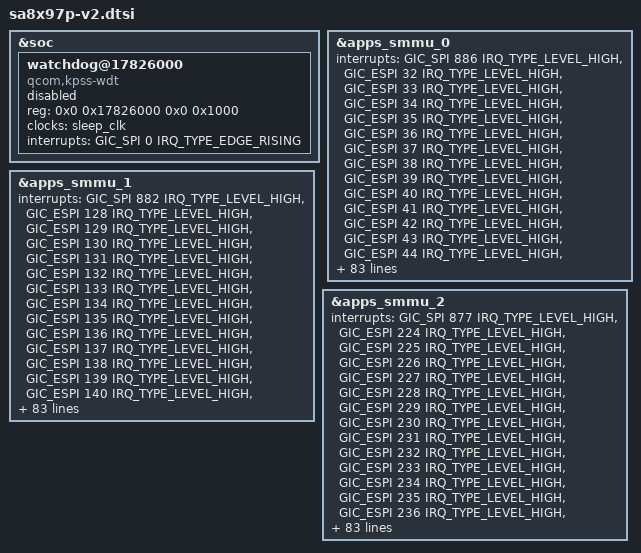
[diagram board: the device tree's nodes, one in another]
// SPDX-License-Identifier: BSD-3-Clause
/*
 * Copyright (c) Qualcomm Technologies, Inc. and/or its subsidiaries.
 */

&soc {
	/delete-node/ watchdog@17821000;

	watchdog@17826000 {
		compatible = "qcom,kpss-wdt";
		reg = <0x0 0x17826000 0x0 0x1000>;
		clocks = <&sleep_clk>;
		interrupts = <GIC_SPI 0 IRQ_TYPE_EDGE_RISING>;
		status = "disabled";
	};
};

&apps_smmu_0 {
	interrupts =	<GIC_SPI 886 IRQ_TYPE_LEVEL_HIGH>,
			<GIC_ESPI 32 IRQ_TYPE_LEVEL_HIGH>,
			<GIC_ESPI 33 IRQ_TYPE_LEVEL_HIGH>,
			<GIC_ESPI 34 IRQ_TYPE_LEVEL_HIGH>,
			<GIC_ESPI 35 IRQ_TYPE_LEVEL_HIGH>,
			<GIC_ESPI 36 IRQ_TYPE_LEVEL_HIGH>,
			<GIC_ESPI 37 IRQ_TYPE_LEVEL_HIGH>,
			<GIC_ESPI 38 IRQ_TYPE_LEVEL_HIGH>,
			<GIC_ESPI 39 IRQ_TYPE_LEVEL_HIGH>,
			<GIC_ESPI 40 IRQ_TYPE_LEVEL_HIGH>,
			<GIC_ESPI 41 IRQ_TYPE_LEVEL_HIGH>,
			<GIC_ESPI 42 IRQ_TYPE_LEVEL_HIGH>,
			<GIC_ESPI 43 IRQ_TYPE_LEVEL_HIGH>,
			<GIC_ESPI 44 IRQ_TYPE_LEVEL_HIGH>,
			<GIC_ESPI 45 IRQ_TYPE_LEVEL_HIGH>,
			<GIC_ESPI 46 IRQ_TYPE_LEVEL_HIGH>,
			<GIC_ESPI 47 IRQ_TYPE_LEVEL_HIGH>,
			<GIC_ESPI 48 IRQ_TYPE_LEVEL_HIGH>,
			<GIC_ESPI 49 IRQ_TYPE_LEVEL_HIGH>,
			<GIC_ESPI 50 IRQ_TYPE_LEVEL_HIGH>,
			<GIC_ESPI 51 IRQ_TYPE_LEVEL_HIGH>,
			<GIC_ESPI 52 IRQ_TYPE_LEVEL_HIGH>,
			<GIC_ESPI 53 IRQ_TYPE_LEVEL_HIGH>,
			<GIC_ESPI 54 IRQ_TYPE_LEVEL_HIGH>,
			<GIC_ESPI 55 IRQ_TYPE_LEVEL_HIGH>,
			<GIC_ESPI 56 IRQ_TYPE_LEVEL_HIGH>,
			<GIC_ESPI 57 IRQ_TYPE_LEVEL_HIGH>,
			<GIC_ESPI 58 IRQ_TYPE_LEVEL_HIGH>,
			<GIC_ESPI 59 IRQ_TYPE_LEVEL_HIGH>,
			<GIC_ESPI 60 IRQ_TYPE_LEVEL_HIGH>,
			<GIC_ESPI 61 IRQ_TYPE_LEVEL_HIGH>,
			<GIC_ESPI 62 IRQ_TYPE_LEVEL_HIGH>,
			<GIC_ESPI 63 IRQ_TYPE_LEVEL_HIGH>,
			<GIC_ESPI 64 IRQ_TYPE_LEVEL_HIGH>,
			<GIC_ESPI 65 IRQ_TYPE_LEVEL_HIGH>,
			<GIC_ESPI 66 IRQ_TYPE_LEVEL_HIGH>,
			<GIC_ESPI 67 IRQ_TYPE_LEVEL_HIGH>,
			<GIC_ESPI 68 IRQ_TYPE_LEVEL_HIGH>,
			<GIC_ESPI 69 IRQ_TYPE_LEVEL_HIGH>,
			<GIC_ESPI 70 IRQ_TYPE_LEVEL_HIGH>,
			<GIC_ESPI 71 IRQ_TYPE_LEVEL_HIGH>,
			<GIC_ESPI 72 IRQ_TYPE_LEVEL_HIGH>,
			<GIC_ESPI 73 IRQ_TYPE_LEVEL_HIGH>,
			<GIC_ESPI 74 IRQ_TYPE_LEVEL_HIGH>,
			<GIC_ESPI 75 IRQ_TYPE_LEVEL_HIGH>,
			<GIC_ESPI 76 IRQ_TYPE_LEVEL_HIGH>,
			<GIC_ESPI 77 IRQ_TYPE_LEVEL_HIGH>,
			<GIC_ESPI 78 IRQ_TYPE_LEVEL_HIGH>,
			<GIC_ESPI 79 IRQ_TYPE_LEVEL_HIGH>,
			<GIC_ESPI 80 IRQ_TYPE_LEVEL_HIGH>,
			<GIC_ESPI 81 IRQ_TYPE_LEVEL_HIGH>,
			<GIC_ESPI 82 IRQ_TYPE_LEVEL_HIGH>,
			<GIC_ESPI 83 IRQ_TYPE_LEVEL_HIGH>,
			<GIC_ESPI 84 IRQ_TYPE_LEVEL_HIGH>,
			<GIC_ESPI 85 IRQ_TYPE_LEVEL_HIGH>,
			<GIC_ESPI 86 IRQ_TYPE_LEVEL_HIGH>,
			<GIC_ESPI 87 IRQ_TYPE_LEVEL_HIGH>,
			<GIC_ESPI 88 IRQ_TYPE_LEVEL_HIGH>,
			<GIC_ESPI 89 IRQ_TYPE_LEVEL_HIGH>,
			<GIC_ESPI 90 IRQ_TYPE_LEVEL_HIGH>,
			<GIC_ESPI 91 IRQ_TYPE_LEVEL_HIGH>,
			<GIC_ESPI 92 IRQ_TYPE_LEVEL_HIGH>,
			<GIC_ESPI 93 IRQ_TYPE_LEVEL_HIGH>,
			<GIC_ESPI 94 IRQ_TYPE_LEVEL_HIGH>,
			<GIC_ESPI 95 IRQ_TYPE_LEVEL_HIGH>,
			<GIC_ESPI 96 IRQ_TYPE_LEVEL_HIGH>,
			<GIC_ESPI 97 IRQ_TYPE_LEVEL_HIGH>,
			<GIC_ESPI 98 IRQ_TYPE_LEVEL_HIGH>,
			<GIC_ESPI 99 IRQ_TYPE_LEVEL_HIGH>,
			<GIC_ESPI 100 IRQ_TYPE_LEVEL_HIGH>,
			<GIC_ESPI 101 IRQ_TYPE_LEVEL_HIGH>,
			<GIC_ESPI 102 IRQ_TYPE_LEVEL_HIGH>,
			<GIC_ESPI 103 IRQ_TYPE_LEVEL_HIGH>,
			<GIC_ESPI 104 IRQ_TYPE_LEVEL_HIGH>,
			<GIC_ESPI 105 IRQ_TYPE_LEVEL_HIGH>,
			<GIC_ESPI 106 IRQ_TYPE_LEVEL_HIGH>,
			<GIC_ESPI 107 IRQ_TYPE_LEVEL_HIGH>,
			<GIC_ESPI 108 IRQ_TYPE_LEVEL_HIGH>,
			<GIC_ESPI 109 IRQ_TYPE_LEVEL_HIGH>,
			<GIC_ESPI 110 IRQ_TYPE_LEVEL_HIGH>,
			<GIC_ESPI 111 IRQ_TYPE_LEVEL_HIGH>,
			<GIC_ESPI 112 IRQ_TYPE_LEVEL_HIGH>,
			<GIC_ESPI 113 IRQ_TYPE_LEVEL_HIGH>,
			<GIC_ESPI 114 IRQ_TYPE_LEVEL_HIGH>,
			<GIC_ESPI 115 IRQ_TYPE_LEVEL_HIGH>,
			<GIC_ESPI 116 IRQ_TYPE_LEVEL_HIGH>,
			<GIC_ESPI 117 IRQ_TYPE_LEVEL_HIGH>,
			<GIC_ESPI 118 IRQ_TYPE_LEVEL_HIGH>,
			<GIC_ESPI 119 IRQ_TYPE_LEVEL_HIGH>,
			<GIC_ESPI 120 IRQ_TYPE_LEVEL_HIGH>,
			<GIC_ESPI 121 IRQ_TYPE_LEVEL_HIGH>,
			<GIC_ESPI 122 IRQ_TYPE_LEVEL_HIGH>,
			<GIC_ESPI 123 IRQ_TYPE_LEVEL_HIGH>,
			<GIC_ESPI 124 IRQ_TYPE_LEVEL_HIGH>,
			<GIC_ESPI 125 IRQ_TYPE_LEVEL_HIGH>,
			<GIC_ESPI 126 IRQ_TYPE_LEVEL_HIGH>,
			<GIC_ESPI 127 IRQ_TYPE_LEVEL_HIGH>;
};

&apps_smmu_1 {
	interrupts =	<GIC_SPI 882 IRQ_TYPE_LEVEL_HIGH>,
			<GIC_ESPI 128 IRQ_TYPE_LEVEL_HIGH>,
			<GIC_ESPI 129 IRQ_TYPE_LEVEL_HIGH>,
			<GIC_ESPI 130 IRQ_TYPE_LEVEL_HIGH>,
			<GIC_ESPI 131 IRQ_TYPE_LEVEL_HIGH>,
			<GIC_ESPI 132 IRQ_TYPE_LEVEL_HIGH>,
			<GIC_ESPI 133 IRQ_TYPE_LEVEL_HIGH>,
			<GIC_ESPI 134 IRQ_TYPE_LEVEL_HIGH>,
			<GIC_ESPI 135 IRQ_TYPE_LEVEL_HIGH>,
			<GIC_ESPI 136 IRQ_TYPE_LEVEL_HIGH>,
			<GIC_ESPI 137 IRQ_TYPE_LEVEL_HIGH>,
			<GIC_ESPI 138 IRQ_TYPE_LEVEL_HIGH>,
			<GIC_ESPI 139 IRQ_TYPE_LEVEL_HIGH>,
			<GIC_ESPI 140 IRQ_TYPE_LEVEL_HIGH>,
			<GIC_ESPI 141 IRQ_TYPE_LEVEL_HIGH>,
			<GIC_ESPI 142 IRQ_TYPE_LEVEL_HIGH>,
			<GIC_ESPI 143 IRQ_TYPE_LEVEL_HIGH>,
			<GIC_ESPI 144 IRQ_TYPE_LEVEL_HIGH>,
			<GIC_ESPI 145 IRQ_TYPE_LEVEL_HIGH>,
			<GIC_ESPI 146 IRQ_TYPE_LEVEL_HIGH>,
			<GIC_ESPI 147 IRQ_TYPE_LEVEL_HIGH>,
			<GIC_ESPI 148 IRQ_TYPE_LEVEL_HIGH>,
			<GIC_ESPI 149 IRQ_TYPE_LEVEL_HIGH>,
			<GIC_ESPI 150 IRQ_TYPE_LEVEL_HIGH>,
			<GIC_ESPI 151 IRQ_TYPE_LEVEL_HIGH>,
			<GIC_ESPI 152 IRQ_TYPE_LEVEL_HIGH>,
			<GIC_ESPI 153 IRQ_TYPE_LEVEL_HIGH>,
			<GIC_ESPI 154 IRQ_TYPE_LEVEL_HIGH>,
			<GIC_ESPI 155 IRQ_TYPE_LEVEL_HIGH>,
			<GIC_ESPI 156 IRQ_TYPE_LEVEL_HIGH>,
			<GIC_ESPI 157 IRQ_TYPE_LEVEL_HIGH>,
			<GIC_ESPI 158 IRQ_TYPE_LEVEL_HIGH>,
			<GIC_ESPI 159 IRQ_TYPE_LEVEL_HIGH>,
			<GIC_ESPI 160 IRQ_TYPE_LEVEL_HIGH>,
			<GIC_ESPI 161 IRQ_TYPE_LEVEL_HIGH>,
			<GIC_ESPI 162 IRQ_TYPE_LEVEL_HIGH>,
			<GIC_ESPI 163 IRQ_TYPE_LEVEL_HIGH>,
			<GIC_ESPI 164 IRQ_TYPE_LEVEL_HIGH>,
			<GIC_ESPI 165 IRQ_TYPE_LEVEL_HIGH>,
			<GIC_ESPI 166 IRQ_TYPE_LEVEL_HIGH>,
			<GIC_ESPI 167 IRQ_TYPE_LEVEL_HIGH>,
			<GIC_ESPI 168 IRQ_TYPE_LEVEL_HIGH>,
			<GIC_ESPI 169 IRQ_TYPE_LEVEL_HIGH>,
			<GIC_ESPI 170 IRQ_TYPE_LEVEL_HIGH>,
			<GIC_ESPI 171 IRQ_TYPE_LEVEL_HIGH>,
			<GIC_ESPI 172 IRQ_TYPE_LEVEL_HIGH>,
			<GIC_ESPI 173 IRQ_TYPE_LEVEL_HIGH>,
			<GIC_ESPI 174 IRQ_TYPE_LEVEL_HIGH>,
			<GIC_ESPI 175 IRQ_TYPE_LEVEL_HIGH>,
			<GIC_ESPI 176 IRQ_TYPE_LEVEL_HIGH>,
			<GIC_ESPI 177 IRQ_TYPE_LEVEL_HIGH>,
			<GIC_ESPI 178 IRQ_TYPE_LEVEL_HIGH>,
			<GIC_ESPI 179 IRQ_TYPE_LEVEL_HIGH>,
			<GIC_ESPI 180 IRQ_TYPE_LEVEL_HIGH>,
			<GIC_ESPI 181 IRQ_TYPE_LEVEL_HIGH>,
			<GIC_ESPI 182 IRQ_TYPE_LEVEL_HIGH>,
			<GIC_ESPI 183 IRQ_TYPE_LEVEL_HIGH>,
			<GIC_ESPI 184 IRQ_TYPE_LEVEL_HIGH>,
			<GIC_ESPI 185 IRQ_TYPE_LEVEL_HIGH>,
			<GIC_ESPI 186 IRQ_TYPE_LEVEL_HIGH>,
			<GIC_ESPI 187 IRQ_TYPE_LEVEL_HIGH>,
			<GIC_ESPI 188 IRQ_TYPE_LEVEL_HIGH>,
			<GIC_ESPI 189 IRQ_TYPE_LEVEL_HIGH>,
			<GIC_ESPI 190 IRQ_TYPE_LEVEL_HIGH>,
			<GIC_ESPI 191 IRQ_TYPE_LEVEL_HIGH>,
			<GIC_ESPI 192 IRQ_TYPE_LEVEL_HIGH>,
			<GIC_ESPI 193 IRQ_TYPE_LEVEL_HIGH>,
			<GIC_ESPI 194 IRQ_TYPE_LEVEL_HIGH>,
			<GIC_ESPI 195 IRQ_TYPE_LEVEL_HIGH>,
			<GIC_ESPI 196 IRQ_TYPE_LEVEL_HIGH>,
			<GIC_ESPI 197 IRQ_TYPE_LEVEL_HIGH>,
			<GIC_ESPI 198 IRQ_TYPE_LEVEL_HIGH>,
			<GIC_ESPI 199 IRQ_TYPE_LEVEL_HIGH>,
			<GIC_ESPI 200 IRQ_TYPE_LEVEL_HIGH>,
			<GIC_ESPI 201 IRQ_TYPE_LEVEL_HIGH>,
			<GIC_ESPI 202 IRQ_TYPE_LEVEL_HIGH>,
			<GIC_ESPI 203 IRQ_TYPE_LEVEL_HIGH>,
			<GIC_ESPI 204 IRQ_TYPE_LEVEL_HIGH>,
			<GIC_ESPI 205 IRQ_TYPE_LEVEL_HIGH>,
			<GIC_ESPI 206 IRQ_TYPE_LEVEL_HIGH>,
			<GIC_ESPI 207 IRQ_TYPE_LEVEL_HIGH>,
			<GIC_ESPI 208 IRQ_TYPE_LEVEL_HIGH>,
			<GIC_ESPI 209 IRQ_TYPE_LEVEL_HIGH>,
			<GIC_ESPI 210 IRQ_TYPE_LEVEL_HIGH>,
			<GIC_ESPI 211 IRQ_TYPE_LEVEL_HIGH>,
			<GIC_ESPI 212 IRQ_TYPE_LEVEL_HIGH>,
			<GIC_ESPI 213 IRQ_TYPE_LEVEL_HIGH>,
			<GIC_ESPI 214 IRQ_TYPE_LEVEL_HIGH>,
			<GIC_ESPI 215 IRQ_TYPE_LEVEL_HIGH>,
			<GIC_ESPI 216 IRQ_TYPE_LEVEL_HIGH>,
			<GIC_ESPI 217 IRQ_TYPE_LEVEL_HIGH>,
			<GIC_ESPI 218 IRQ_TYPE_LEVEL_HIGH>,
			<GIC_ESPI 219 IRQ_TYPE_LEVEL_HIGH>,
			<GIC_ESPI 220 IRQ_TYPE_LEVEL_HIGH>,
			<GIC_ESPI 221 IRQ_TYPE_LEVEL_HIGH>,
			<GIC_ESPI 222 IRQ_TYPE_LEVEL_HIGH>,
			<GIC_ESPI 223 IRQ_TYPE_LEVEL_HIGH>;
};

&apps_smmu_2 {
	interrupts =	<GIC_SPI 877 IRQ_TYPE_LEVEL_HIGH>,
			<GIC_ESPI 224 IRQ_TYPE_LEVEL_HIGH>,
			<GIC_ESPI 225 IRQ_TYPE_LEVEL_HIGH>,
			<GIC_ESPI 226 IRQ_TYPE_LEVEL_HIGH>,
			<GIC_ESPI 227 IRQ_TYPE_LEVEL_HIGH>,
			<GIC_ESPI 228 IRQ_TYPE_LEVEL_HIGH>,
			<GIC_ESPI 229 IRQ_TYPE_LEVEL_HIGH>,
			<GIC_ESPI 230 IRQ_TYPE_LEVEL_HIGH>,
			<GIC_ESPI 231 IRQ_TYPE_LEVEL_HIGH>,
			<GIC_ESPI 232 IRQ_TYPE_LEVEL_HIGH>,
			<GIC_ESPI 233 IRQ_TYPE_LEVEL_HIGH>,
			<GIC_ESPI 234 IRQ_TYPE_LEVEL_HIGH>,
			<GIC_ESPI 235 IRQ_TYPE_LEVEL_HIGH>,
			<GIC_ESPI 236 IRQ_TYPE_LEVEL_HIGH>,
			<GIC_ESPI 237 IRQ_TYPE_LEVEL_HIGH>,
			<GIC_ESPI 238 IRQ_TYPE_LEVEL_HIGH>,
			<GIC_ESPI 239 IRQ_TYPE_LEVEL_HIGH>,
			<GIC_ESPI 240 IRQ_TYPE_LEVEL_HIGH>,
			<GIC_ESPI 241 IRQ_TYPE_LEVEL_HIGH>,
			<GIC_ESPI 242 IRQ_TYPE_LEVEL_HIGH>,
			<GIC_ESPI 243 IRQ_TYPE_LEVEL_HIGH>,
			<GIC_ESPI 244 IRQ_TYPE_LEVEL_HIGH>,
			<GIC_ESPI 245 IRQ_TYPE_LEVEL_HIGH>,
			<GIC_ESPI 246 IRQ_TYPE_LEVEL_HIGH>,
			<GIC_ESPI 247 IRQ_TYPE_LEVEL_HIGH>,
			<GIC_ESPI 248 IRQ_TYPE_LEVEL_HIGH>,
			<GIC_ESPI 249 IRQ_TYPE_LEVEL_HIGH>,
			<GIC_ESPI 250 IRQ_TYPE_LEVEL_HIGH>,
			<GIC_ESPI 251 IRQ_TYPE_LEVEL_HIGH>,
			<GIC_ESPI 252 IRQ_TYPE_LEVEL_HIGH>,
			<GIC_ESPI 253 IRQ_TYPE_LEVEL_HIGH>,
			<GIC_ESPI 254 IRQ_TYPE_LEVEL_HIGH>,
			<GIC_ESPI 255 IRQ_TYPE_LEVEL_HIGH>,
			<GIC_ESPI 256 IRQ_TYPE_LEVEL_HIGH>,
			<GIC_ESPI 257 IRQ_TYPE_LEVEL_HIGH>,
			<GIC_ESPI 258 IRQ_TYPE_LEVEL_HIGH>,
			<GIC_ESPI 259 IRQ_TYPE_LEVEL_HIGH>,
			<GIC_ESPI 260 IRQ_TYPE_LEVEL_HIGH>,
			<GIC_ESPI 261 IRQ_TYPE_LEVEL_HIGH>,
			<GIC_ESPI 262 IRQ_TYPE_LEVEL_HIGH>,
			<GIC_ESPI 263 IRQ_TYPE_LEVEL_HIGH>,
			<GIC_ESPI 264 IRQ_TYPE_LEVEL_HIGH>,
			<GIC_ESPI 265 IRQ_TYPE_LEVEL_HIGH>,
			<GIC_ESPI 266 IRQ_TYPE_LEVEL_HIGH>,
			<GIC_ESPI 267 IRQ_TYPE_LEVEL_HIGH>,
			<GIC_ESPI 268 IRQ_TYPE_LEVEL_HIGH>,
			<GIC_ESPI 269 IRQ_TYPE_LEVEL_HIGH>,
			<GIC_ESPI 270 IRQ_TYPE_LEVEL_HIGH>,
			<GIC_ESPI 271 IRQ_TYPE_LEVEL_HIGH>,
			<GIC_ESPI 272 IRQ_TYPE_LEVEL_HIGH>,
			<GIC_ESPI 273 IRQ_TYPE_LEVEL_HIGH>,
			<GIC_ESPI 274 IRQ_TYPE_LEVEL_HIGH>,
			<GIC_ESPI 275 IRQ_TYPE_LEVEL_HIGH>,
			<GIC_ESPI 276 IRQ_TYPE_LEVEL_HIGH>,
			<GIC_ESPI 277 IRQ_TYPE_LEVEL_HIGH>,
			<GIC_ESPI 278 IRQ_TYPE_LEVEL_HIGH>,
			<GIC_ESPI 279 IRQ_TYPE_LEVEL_HIGH>,
			<GIC_ESPI 280 IRQ_TYPE_LEVEL_HIGH>,
			<GIC_ESPI 281 IRQ_TYPE_LEVEL_HIGH>,
			<GIC_ESPI 282 IRQ_TYPE_LEVEL_HIGH>,
			<GIC_ESPI 283 IRQ_TYPE_LEVEL_HIGH>,
			<GIC_ESPI 284 IRQ_TYPE_LEVEL_HIGH>,
			<GIC_ESPI 285 IRQ_TYPE_LEVEL_HIGH>,
			<GIC_ESPI 286 IRQ_TYPE_LEVEL_HIGH>,
			<GIC_ESPI 287 IRQ_TYPE_LEVEL_HIGH>,
			<GIC_ESPI 288 IRQ_TYPE_LEVEL_HIGH>,
			<GIC_ESPI 289 IRQ_TYPE_LEVEL_HIGH>,
			<GIC_ESPI 290 IRQ_TYPE_LEVEL_HIGH>,
			<GIC_ESPI 291 IRQ_TYPE_LEVEL_HIGH>,
			<GIC_ESPI 292 IRQ_TYPE_LEVEL_HIGH>,
			<GIC_ESPI 293 IRQ_TYPE_LEVEL_HIGH>,
			<GIC_ESPI 294 IRQ_TYPE_LEVEL_HIGH>,
			<GIC_ESPI 295 IRQ_TYPE_LEVEL_HIGH>,
			<GIC_ESPI 296 IRQ_TYPE_LEVEL_HIGH>,
			<GIC_ESPI 297 IRQ_TYPE_LEVEL_HIGH>,
			<GIC_ESPI 298 IRQ_TYPE_LEVEL_HIGH>,
			<GIC_ESPI 299 IRQ_TYPE_LEVEL_HIGH>,
			<GIC_ESPI 300 IRQ_TYPE_LEVEL_HIGH>,
			<GIC_ESPI 301 IRQ_TYPE_LEVEL_HIGH>,
			<GIC_ESPI 302 IRQ_TYPE_LEVEL_HIGH>,
			<GIC_ESPI 303 IRQ_TYPE_LEVEL_HIGH>,
			<GIC_ESPI 304 IRQ_TYPE_LEVEL_HIGH>,
			<GIC_ESPI 305 IRQ_TYPE_LEVEL_HIGH>,
			<GIC_ESPI 306 IRQ_TYPE_LEVEL_HIGH>,
			<GIC_ESPI 307 IRQ_TYPE_LEVEL_HIGH>,
			<GIC_ESPI 308 IRQ_TYPE_LEVEL_HIGH>,
			<GIC_ESPI 309 IRQ_TYPE_LEVEL_HIGH>,
			<GIC_ESPI 310 IRQ_TYPE_LEVEL_HIGH>,
			<GIC_ESPI 311 IRQ_TYPE_LEVEL_HIGH>,
			<GIC_ESPI 312 IRQ_TYPE_LEVEL_HIGH>,
			<GIC_ESPI 313 IRQ_TYPE_LEVEL_HIGH>,
			<GIC_ESPI 314 IRQ_TYPE_LEVEL_HIGH>,
			<GIC_ESPI 315 IRQ_TYPE_LEVEL_HIGH>,
			<GIC_ESPI 316 IRQ_TYPE_LEVEL_HIGH>,
			<GIC_ESPI 317 IRQ_TYPE_LEVEL_HIGH>,
			<GIC_ESPI 318 IRQ_TYPE_LEVEL_HIGH>,
			<GIC_ESPI 319 IRQ_TYPE_LEVEL_HIGH>;

};
